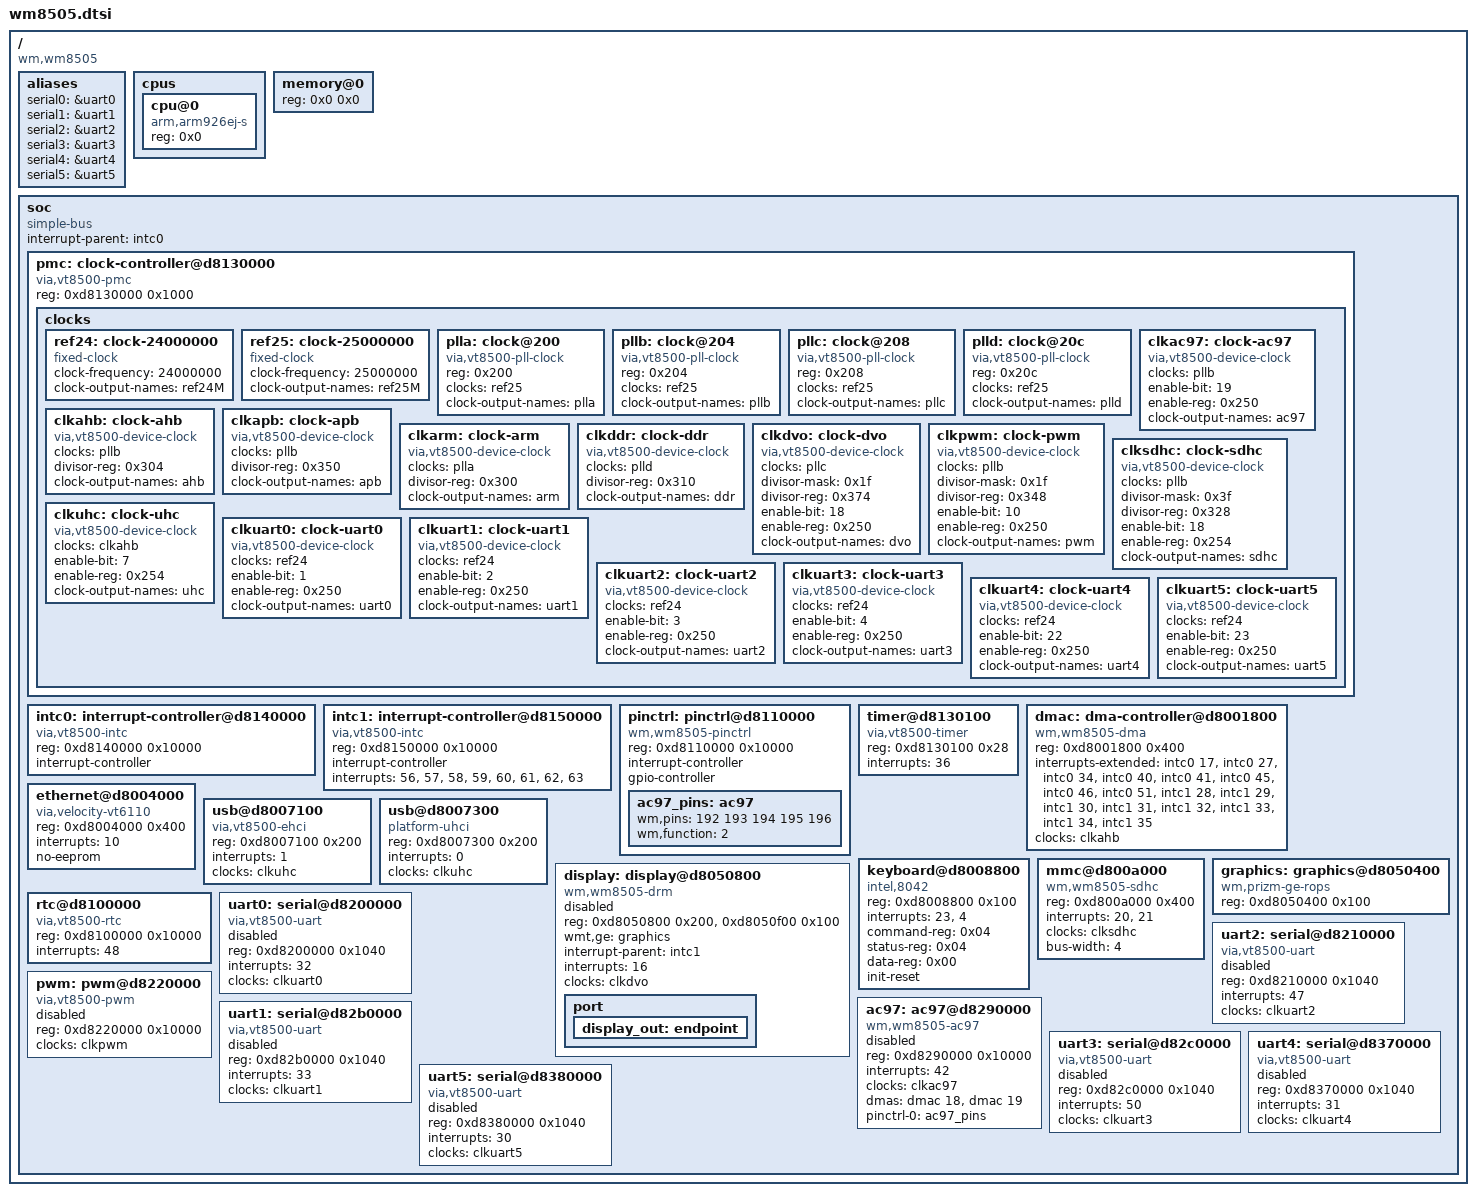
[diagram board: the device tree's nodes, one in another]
// SPDX-License-Identifier: GPL-2.0-or-later
/*
 * wm8505.dtsi - Device tree file for WonderMedia WM8505 SoC
 *
 * Copyright (C) 2012 Tony Prisk <linux@prisktech.co.nz>
 * Copyright (C) 2026 Logan Russell <me@lrussell.net>
 */

#include <dt-bindings/gpio/gpio.h>
#include <dt-bindings/interrupt-controller/irq.h>

/ {
	compatible = "wm,wm8505";
	#address-cells = <1>;
	#size-cells = <1>;

	aliases {
		serial0 = &uart0;
		serial1 = &uart1;
		serial2 = &uart2;
		serial3 = &uart3;
		serial4 = &uart4;
		serial5 = &uart5;
	};

	cpus {
		#address-cells = <1>;
		#size-cells = <0>;

		cpu@0 {
			compatible = "arm,arm926ej-s";
			device_type = "cpu";
			reg = <0x0>;
		};
	};

	memory@0 {
		device_type = "memory";
		reg = <0x0 0x0>;
	};

	soc {
		compatible = "simple-bus";
		#address-cells = <1>;
		#size-cells = <1>;
		ranges;
		interrupt-parent = <&intc0>;

		pmc: clock-controller@d8130000 {
			compatible = "via,vt8500-pmc";
			reg = <0xd8130000 0x1000>;

			clocks {
				#address-cells = <1>;
				#size-cells = <0>;

				ref24: clock-24000000 {
					compatible = "fixed-clock";
					#clock-cells = <0>;
					clock-frequency = <24000000>;
					clock-output-names = "ref24M";
				};

				ref25: clock-25000000 {
					compatible = "fixed-clock";
					#clock-cells = <0>;
					clock-frequency = <25000000>;
					clock-output-names = "ref25M";
				};

				plla: clock@200 {
					compatible = "via,vt8500-pll-clock";
					reg = <0x200>;
					#clock-cells = <0>;
					clocks = <&ref25>;
					clock-output-names = "plla";
				};

				pllb: clock@204 {
					compatible = "via,vt8500-pll-clock";
					reg = <0x204>;
					#clock-cells = <0>;
					clocks = <&ref25>;
					clock-output-names = "pllb";
				};

				pllc: clock@208 {
					compatible = "via,vt8500-pll-clock";
					reg = <0x208>;
					#clock-cells = <0>;
					clocks = <&ref25>;
					clock-output-names = "pllc";
				};

				plld: clock@20c {
					compatible = "via,vt8500-pll-clock";
					reg = <0x20c>;
					#clock-cells = <0>;
					clocks = <&ref25>;
					clock-output-names = "plld";
				};

				clkac97: clock-ac97 {
					compatible = "via,vt8500-device-clock";
					#clock-cells = <0>;
					clocks = <&pllb>;
					enable-bit = <19>;
					enable-reg = <0x250>;
					clock-output-names = "ac97";
				};

				clkahb: clock-ahb {
					compatible = "via,vt8500-device-clock";
					#clock-cells = <0>;
					clocks = <&pllb>;
					divisor-reg = <0x304>;
					clock-output-names = "ahb";
				};

				clkapb: clock-apb {
					compatible = "via,vt8500-device-clock";
					#clock-cells = <0>;
					clocks = <&pllb>;
					divisor-reg = <0x350>;
					clock-output-names = "apb";
				};

				clkarm: clock-arm {
					compatible = "via,vt8500-device-clock";
					#clock-cells = <0>;
					clocks = <&plla>;
					divisor-reg = <0x300>;
					clock-output-names = "arm";
				};

				clkddr: clock-ddr {
					compatible = "via,vt8500-device-clock";
					#clock-cells = <0>;
					clocks = <&plld>;
					divisor-reg = <0x310>;
					clock-output-names = "ddr";
				};

				clkdvo: clock-dvo {
					compatible = "via,vt8500-device-clock";
					#clock-cells = <0>;
					clocks = <&pllc>;
					divisor-mask = <0x1f>;
					divisor-reg = <0x374>;
					enable-bit = <18>;
					enable-reg = <0x250>;
					clock-output-names = "dvo";
				};

				clkpwm: clock-pwm {
					compatible = "via,vt8500-device-clock";
					#clock-cells = <0>;
					clocks = <&pllb>;
					divisor-mask = <0x1f>;
					divisor-reg = <0x348>;
					enable-bit = <10>;
					enable-reg = <0x250>;
					clock-output-names = "pwm";
				};

				clksdhc: clock-sdhc {
					compatible = "via,vt8500-device-clock";
					#clock-cells = <0>;
					clocks = <&pllb>;
					divisor-mask = <0x3f>;
					divisor-reg = <0x328>;
					enable-bit = <18>;
					enable-reg = <0x254>;
					clock-output-names = "sdhc";
				};

				clkuhc: clock-uhc {
					compatible = "via,vt8500-device-clock";
					#clock-cells = <0>;
					clocks = <&clkahb>;
					enable-bit = <7>;
					enable-reg = <0x254>;
					clock-output-names = "uhc";
				};

				clkuart0: clock-uart0 {
					compatible = "via,vt8500-device-clock";
					#clock-cells = <0>;
					clocks = <&ref24>;
					enable-bit = <1>;
					enable-reg = <0x250>;
					clock-output-names = "uart0";
				};

				clkuart1: clock-uart1 {
					compatible = "via,vt8500-device-clock";
					#clock-cells = <0>;
					clocks = <&ref24>;
					enable-bit = <2>;
					enable-reg = <0x250>;
					clock-output-names = "uart1";
				};

				clkuart2: clock-uart2 {
					compatible = "via,vt8500-device-clock";
					#clock-cells = <0>;
					clocks = <&ref24>;
					enable-bit = <3>;
					enable-reg = <0x250>;
					clock-output-names = "uart2";
				};

				clkuart3: clock-uart3 {
					compatible = "via,vt8500-device-clock";
					#clock-cells = <0>;
					clocks = <&ref24>;
					enable-bit = <4>;
					enable-reg = <0x250>;
					clock-output-names = "uart3";
				};

				clkuart4: clock-uart4 {
					compatible = "via,vt8500-device-clock";
					#clock-cells = <0>;
					clocks = <&ref24>;
					enable-bit = <22>;
					enable-reg = <0x250>;
					clock-output-names = "uart4";
				};

				clkuart5: clock-uart5 {
					compatible = "via,vt8500-device-clock";
					#clock-cells = <0>;
					clocks = <&ref24>;
					enable-bit = <23>;
					enable-reg = <0x250>;
					clock-output-names = "uart5";
				};
			};
		};

		intc0: interrupt-controller@d8140000 {
			compatible = "via,vt8500-intc";
			reg = <0xd8140000 0x10000>;
			interrupt-controller;
			#interrupt-cells = <1>;
		};

		intc1: interrupt-controller@d8150000 {
			compatible = "via,vt8500-intc";
			reg = <0xd8150000 0x10000>;
			interrupt-controller;
			#interrupt-cells = <1>;
			/* Secondary IC cascaded to intc0 */
			interrupts = <56>, <57>, <58>, <59>, <60>, <61>, <62>, <63>;
		};

		pinctrl: pinctrl@d8110000 {
			compatible = "wm,wm8505-pinctrl";
			reg = <0xd8110000 0x10000>;
			interrupt-controller;
			#interrupt-cells = <2>;
			gpio-controller;
			#gpio-cells = <2>;

			ac97_pins: ac97 {
				wm,pins = <192 193 194 195 196>;
				wm,function = <2>;
			};
		};

		timer@d8130100 {
			compatible = "via,vt8500-timer";
			reg = <0xd8130100 0x28>;
			interrupts = <36>;
		};

		dmac: dma-controller@d8001800 {
			compatible = "wm,wm8505-dma";
			reg = <0xd8001800 0x400>;
			interrupts-extended = <&intc0 17>, <&intc0 27>, <&intc0 34>, <&intc0 40>,
					      <&intc0 41>, <&intc0 45>, <&intc0 46>, <&intc0 51>,
					      <&intc1 28>, <&intc1 29>, <&intc1 30>, <&intc1 31>,
					      <&intc1 32>, <&intc1 33>, <&intc1 34>, <&intc1 35>;
			clocks = <&clkahb>;
			#dma-cells = <1>;
		};

		ethernet@d8004000 {
			compatible = "via,velocity-vt6110";
			reg = <0xd8004000 0x400>;
			interrupts = <10>;
			no-eeprom;
		};

		usb@d8007100 {
			compatible = "via,vt8500-ehci";
			reg = <0xd8007100 0x200>;
			interrupts = <1>;
			clocks = <&clkuhc>;
		};

		usb@d8007300 {
			compatible = "platform-uhci";
			reg = <0xd8007300 0x200>;
			interrupts = <0>;
			clocks = <&clkuhc>;
		};

		keyboard@d8008800 {
			compatible = "intel,8042";
			reg = <0xd8008800 0x100>;
			interrupts = <23>, <4>;
			command-reg = <0x04>;
			status-reg = <0x04>;
			data-reg = <0x00>;
			init-reset;
		};

		mmc@d800a000 {
			compatible = "wm,wm8505-sdhc";
			reg = <0xd800a000 0x400>;
			interrupts = <20>, <21>;
			clocks = <&clksdhc>;
			bus-width = <4>;
		};

		graphics: graphics@d8050400 {
			compatible = "wm,prizm-ge-rops";
			reg = <0xd8050400 0x100>;
		};

		display: display@d8050800 {
			compatible = "wm,wm8505-drm";
			reg = <0xd8050800 0x200>, <0xd8050f00 0x100>;
			reg-names = "govr", "vpp";
			wmt,ge = <&graphics>;
			interrupt-parent = <&intc1>;
			interrupts = <16>;
			clocks = <&clkdvo>;
			status = "disabled";

			port {
				display_out: endpoint { };
			};
		};

		rtc@d8100000 {
			compatible = "via,vt8500-rtc";
			reg = <0xd8100000 0x10000>;
			interrupts = <48>;
		};

		uart0: serial@d8200000 {
			compatible = "via,vt8500-uart";
			reg = <0xd8200000 0x1040>;
			interrupts = <32>;
			clocks = <&clkuart0>;
			status = "disabled";
		};

		uart2: serial@d8210000 {
			compatible = "via,vt8500-uart";
			reg = <0xd8210000 0x1040>;
			interrupts = <47>;
			clocks = <&clkuart2>;
			status = "disabled";
		};

		pwm: pwm@d8220000 {
			compatible = "via,vt8500-pwm";
			reg = <0xd8220000 0x10000>;
			#pwm-cells = <2>;
			clocks = <&clkpwm>;
			status = "disabled";
		};

		ac97: ac97@d8290000 {
			compatible = "wm,wm8505-ac97";
			reg = <0xd8290000 0x10000>;
			interrupts = <42>;
			clocks = <&clkac97>;
			dmas = <&dmac 18>, <&dmac 19>;
			dma-names = "tx", "rx";
			pinctrl-names = "default";
			pinctrl-0 = <&ac97_pins>;
			status = "disabled";
		};

		uart1: serial@d82b0000 {
			compatible = "via,vt8500-uart";
			reg = <0xd82b0000 0x1040>;
			interrupts = <33>;
			clocks = <&clkuart1>;
			status = "disabled";
		};

		uart3: serial@d82c0000 {
			compatible = "via,vt8500-uart";
			reg = <0xd82c0000 0x1040>;
			interrupts = <50>;
			clocks = <&clkuart3>;
			status = "disabled";
		};

		uart4: serial@d8370000 {
			compatible = "via,vt8500-uart";
			reg = <0xd8370000 0x1040>;
			interrupts = <31>;
			clocks = <&clkuart4>;
			status = "disabled";
		};

		uart5: serial@d8380000 {
			compatible = "via,vt8500-uart";
			reg = <0xd8380000 0x1040>;
			interrupts = <30>;
			clocks = <&clkuart5>;
			status = "disabled";
		};
	};
};
